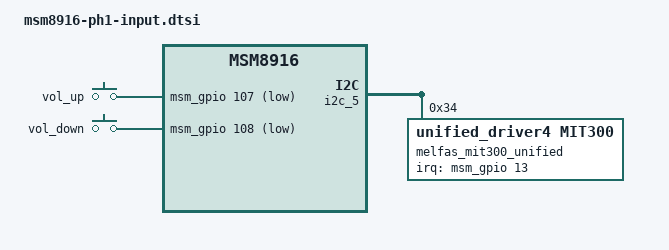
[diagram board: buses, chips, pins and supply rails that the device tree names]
/* Copyright (c) 2012, Code Aurora Forum. All rights reserved.
 *
 * This program is free software; you can redistribute it and/or modify
 * it under the terms of the GNU General Public License version 2 and
 * only version 2 as published by the Free Software Foundation.
 *
 * This program is distributed in the hope that it will be useful,
 * but WITHOUT ANY WARRANTY; without even the implied warranty of
 * MERCHANTABILITY or FITNESS FOR A PARTICULAR PURPOSE.  See the
 * GNU General Public License for more details.
 */

&i2c_5 {
	qcom,clk-freq-out = <400000>;

	melfas_mip4@34 {
		compatible = "melfas,mip4_ts";
		reg = <0x34>;
		interrupt-parent = <&msm_gpio>;
		interrupts = <13 0x2>;
		vd33-supply = <&pm8916_l16>;
		mip4_ts,gpio_irq = <&msm_gpio 13 0x00>;
		mip4_ts,gpio_reset = <&msm_gpio 12 0x00>;
		mip4_ts,max_x = <720>;
		mip4_ts,max_y = <1280>;
		status = "disable";
		pinctrl-names = "pmx_ts_active", "pmx_ts_suspend";		/*Touch GPIO pin name setting*/
		pinctrl-0 = <&ts_int_active>;	/*Touch GPIO pin active setting*/
		pinctrl-1 = <&ts_int_suspend>;	/*Touch GPIO pin suspend setting*/
	};

	melfas_mit300_unified@34 {
		compatible = "unified_driver4,mit300";
		status = "ok";
		revision = "rev_a...";
		reg = <0x34>;
		interrupt-parent = <&msm_gpio>;
		interrupts = <13 0x2>;
	};

	melfas_mit300@34 {
		status = "disable";
		lge,product = "L0M45P1CY5";
		lge,fw_image = "melfas/mit300/ph1/melfas_mip4.bin";
		lge,p5_product = "L0M45P5CY5";
		lge,p5_fw_image = "melfas/mit300/ph1/melfas_mip4.bin";
		use_security_mode = <0>;
		use_security_all = <0>;
	};

	synaptics_td4191_dsx@20 {
		status = "disable";
	};

	synaptics_td4191@20 {
		revision = "...rev_g";
		status = "disable";
		fw_image = "synaptics/lions/PLG463-V1.06-PR1860017-DS5.8.0.0.1135_50057086.img";
		recovery_fw_image = "synaptics/lions/PLG463-V1.06-PR1860017-DS5.8.0.0.1135_50057086.bin";
		panel_spec = "synaptics/lions/lions_limit.txt";
		use_debug_reason = <0>;
	};

	synaptics_td4191_rev_10@20 {
		revision = "rev_10...";
		status = "disable";
		fw_image = "synaptics/lions/PLG516-V1.10-PR1896364-DS5.8.0.0.1135_5005708A.img";
		recovery_fw_image = "synaptics/lions/PLG516-V1.10-PR1896364-DS5.8.0.0.1135_5005708A.bin";
		panel_spec = "synaptics/lions/lions_limit.txt";
		use_debug_reason = <0>;
		use_security_mode = <1>;
		use_security_all = <1>;
	};
};

&soc {
	gpio_keys {
		vol_up {
			gpios = <&msm_gpio 107 0x1>;
		};

		vol_down {
			gpios = <&msm_gpio 108 0x1>;
		};
	};
};
